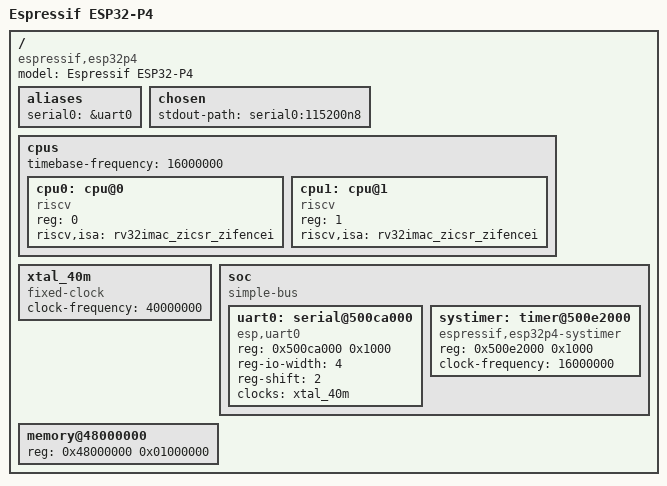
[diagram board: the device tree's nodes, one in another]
// SPDX-License-Identifier: GPL-2.0+
/*
 * ESP32-P4 device tree (M-mode U-Boot, no OpenSBI).
 *
 * U-Boot proper runs from internal SRAM. Linux executes from mapped NOR
 * with a separate DTB in PSRAM.
 */

/dts-v1/;

/ {
	#address-cells = <1>;
	#size-cells = <1>;
	model = "Espressif ESP32-P4";
	compatible = "espressif,esp32p4";

	aliases {
		serial0 = &uart0;
	};

	chosen {
		stdout-path = "serial0:115200n8";
	};

	cpus {
		#address-cells = <1>;
		#size-cells = <0>;
		timebase-frequency = <16000000>;
		bootph-all;

		cpu0: cpu@0 {
			compatible = "riscv";
			device_type = "cpu";
			reg = <0>;
			riscv,isa = "rv32imac_zicsr_zifencei";
			bootph-all;
		};

		cpu1: cpu@1 {
			compatible = "riscv";
			device_type = "cpu";
			reg = <1>;
			riscv,isa = "rv32imac_zicsr_zifencei";
			bootph-all;
		};
	};

	xtal_40m: xtal_40m {
		bootph-all;
		compatible = "fixed-clock";
		clock-frequency = <40000000>;
		#clock-cells = <0>;
	};

	soc {
		bootph-all;
		#address-cells = <1>;
		#size-cells = <1>;
		compatible = "simple-bus";
		ranges;

		uart0: serial@500ca000 {
			bootph-all;
			compatible = "esp,uart0";
			reg = <0x500ca000 0x1000>;
			reg-io-width = <4>;
			reg-shift = <2>;
			clocks = <&xtal_40m>;
		};

		systimer: timer@500e2000 {
			bootph-all;
			compatible = "espressif,esp32p4-systimer";
			reg = <0x500e2000 0x1000>;
			clock-frequency = <16000000>;
		};
	};

	/* Control FDT PSRAM aperture. SPL detects the installed size. */
	memory@48000000 {
		bootph-all;
		device_type = "memory";
		reg = <0x48000000 0x01000000>;
	};
};
